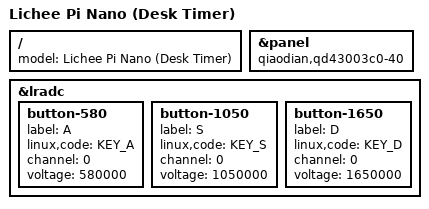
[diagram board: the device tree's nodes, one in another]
// SPDX-License-Identifier: (GPL-2.0+ OR X11)
// based on https://github.com/Lichee-Pi/linux/blob/nano-5.2-flash/arch/arm/boot/dts/suniv-f1c100s-licheepi-nano.dts on 2021-08
/*
 * Copyright 2018 Icenowy Zheng <icenowy@aosc.io>
 */

/dts-v1/;
#include "suniv-f1c100s-licheepi-nano.dts"

/ {
	model = "Lichee Pi Nano (Desk Timer)";
};

&panel {
	// override default resolution (800x480) with smaller resolution: 480x272
	compatible = "qiaodian,qd43003c0-40", "simple-panel";
};

&lradc {
	// keymap for low-resolution ADC input driver
	// (pulling voltage down to different levels 0V-2V on LRADC pin causes this to emit different
	// keyboard codes - pull pin back up to 3.3V when button is off)
	button-580 {
		label = "A";
		linux,code = <KEY_A>;
		channel = <0>;
		voltage = <580000>;
	};

	button-1050 {
		label = "S";
		linux,code = <KEY_S>;
		channel = <0>;
		voltage = <1050000>;
	};

	button-1650 {
		label = "D";
		linux,code = <KEY_D>;
		channel = <0>;
		voltage = <1650000>;
	};
};
